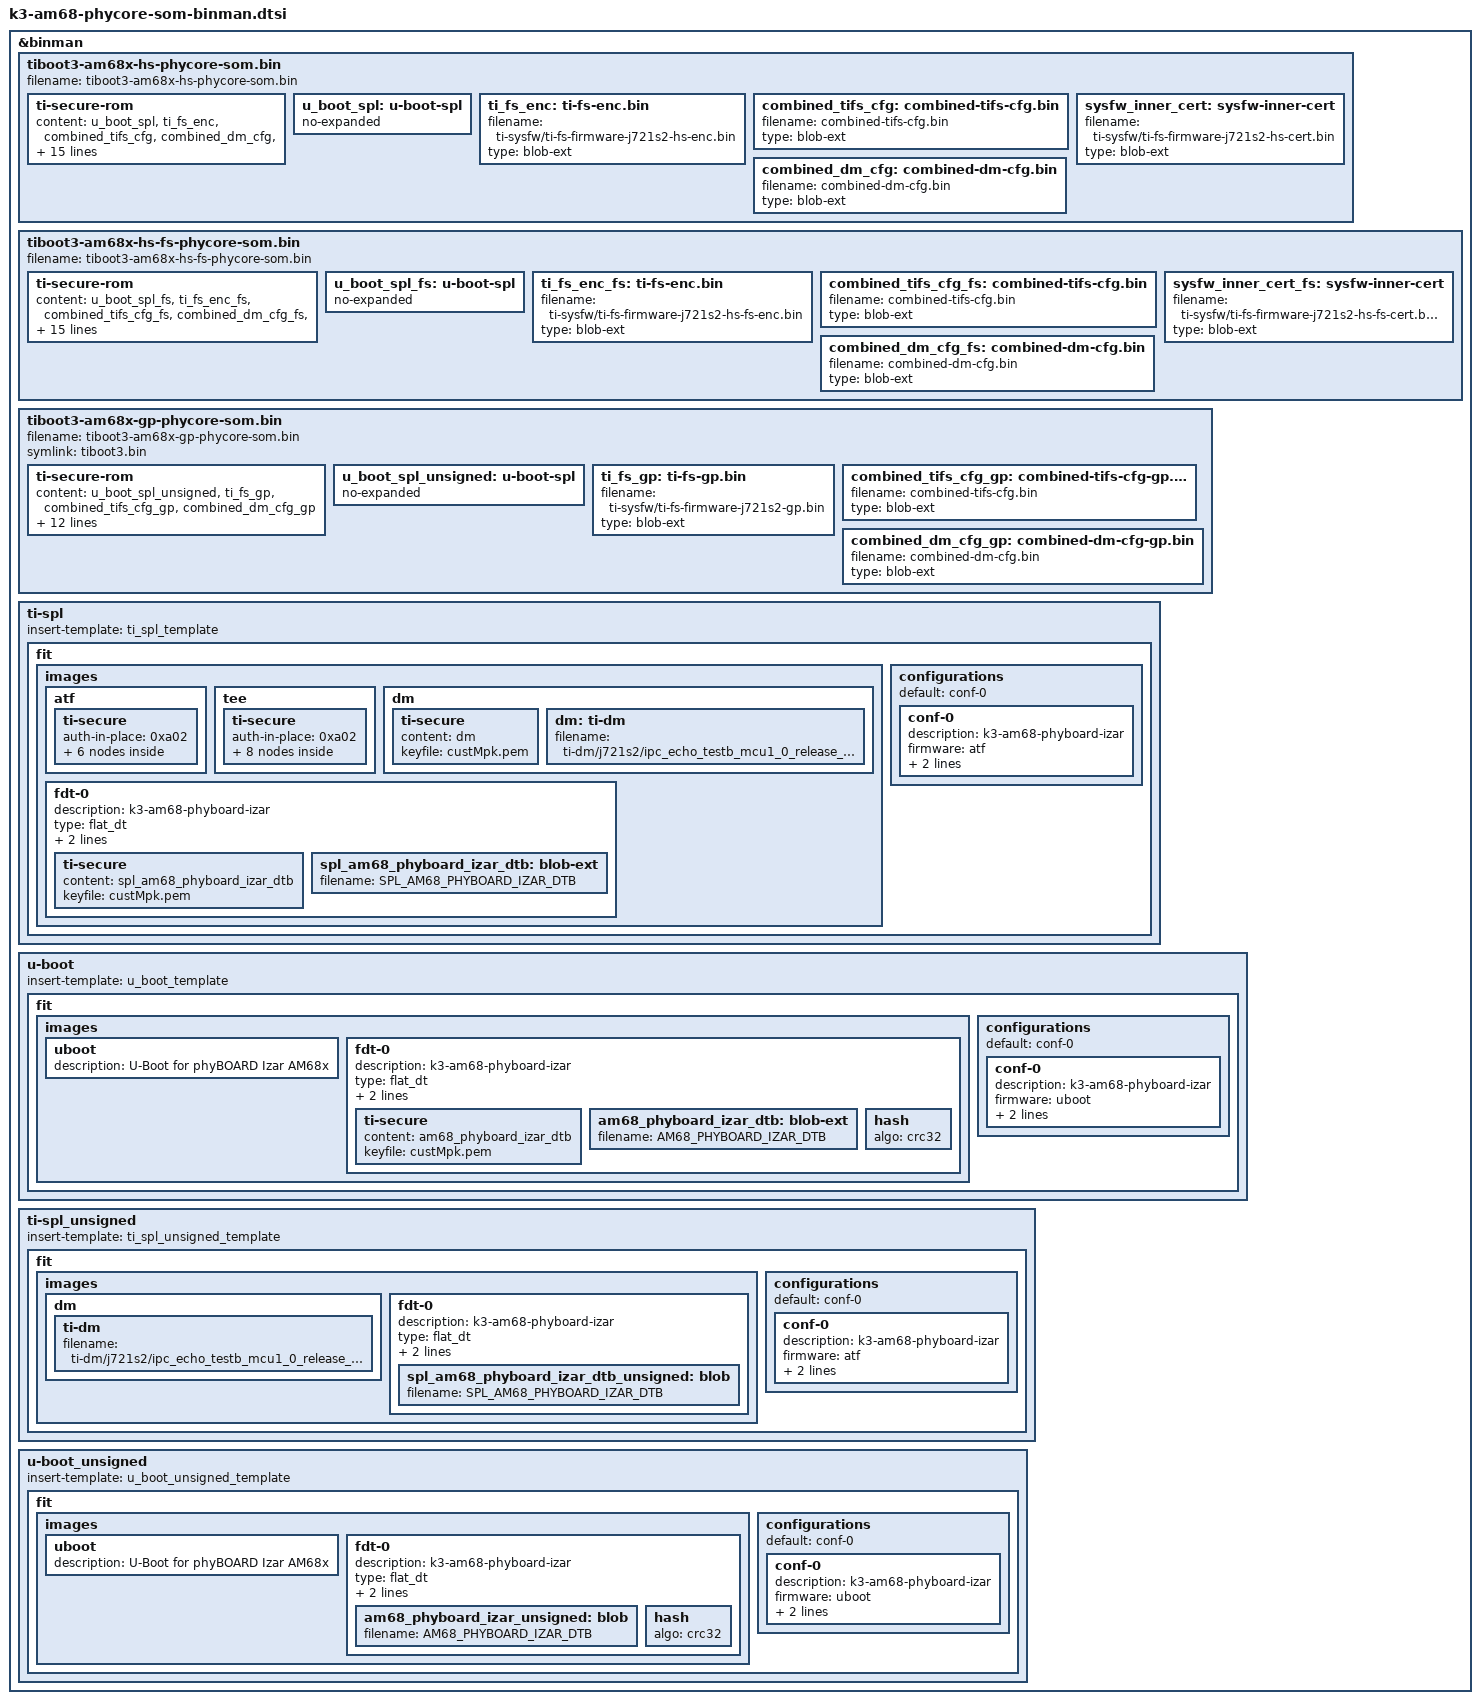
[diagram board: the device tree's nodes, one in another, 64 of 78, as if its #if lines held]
// SPDX-License-Identifier: GPL-2.0-only OR MIT
/*
 * Based on k3-j721s2-binman.dtsi
 *
 * Copyright (C) 2025 PHYTEC Messtechnik GmbH
 * Author: Dominik Haller <d.haller@phytec.de>
 */

#include "k3-binman.dtsi"

#ifdef CONFIG_TARGET_PHYCORE_AM68X_R5

&binman {
	tiboot3-am68x-hs-phycore-som.bin {
		filename = "tiboot3-am68x-hs-phycore-som.bin";
		ti-secure-rom {
			content = <&u_boot_spl>, <&ti_fs_enc>, <&combined_tifs_cfg>,
				<&combined_dm_cfg>, <&sysfw_inner_cert>;
			combined;
			dm-data;
			sysfw-inner-cert;
			keyfile = "custMpk.pem";
			sw-rev = <1>;
			content-sbl = <&u_boot_spl>;
			content-sysfw = <&ti_fs_enc>;
			content-sysfw-data = <&combined_tifs_cfg>;
			content-sysfw-inner-cert = <&sysfw_inner_cert>;
			content-dm-data = <&combined_dm_cfg>;
			load = <CONFIG_SPL_TEXT_BASE>;
			load-sysfw = <0x40000>;
			load-sysfw-data = <0x67000>;
			load-dm-data = <0x41c80000>;
		};
		u_boot_spl: u-boot-spl {
			no-expanded;
		};
		ti_fs_enc: ti-fs-enc.bin {
			filename = "ti-sysfw/ti-fs-firmware-j721s2-hs-enc.bin";
			type = "blob-ext";
		};
		combined_tifs_cfg: combined-tifs-cfg.bin {
			filename = "combined-tifs-cfg.bin";
			type = "blob-ext";
		};
		sysfw_inner_cert: sysfw-inner-cert {
			filename = "ti-sysfw/ti-fs-firmware-j721s2-hs-cert.bin";
			type = "blob-ext";
		};
		combined_dm_cfg: combined-dm-cfg.bin {
			filename = "combined-dm-cfg.bin";
			type = "blob-ext";
		};
	};
};

&binman {
	tiboot3-am68x-hs-fs-phycore-som.bin {
		filename = "tiboot3-am68x-hs-fs-phycore-som.bin";
		ti-secure-rom {
			content = <&u_boot_spl_fs>, <&ti_fs_enc_fs>, <&combined_tifs_cfg_fs>,
				<&combined_dm_cfg_fs>, <&sysfw_inner_cert_fs>;
			combined;
			dm-data;
			sysfw-inner-cert;
			keyfile = "custMpk.pem";
			sw-rev = <1>;
			content-sbl = <&u_boot_spl_fs>;
			content-sysfw = <&ti_fs_enc_fs>;
			content-sysfw-data = <&combined_tifs_cfg_fs>;
			content-sysfw-inner-cert = <&sysfw_inner_cert_fs>;
			content-dm-data = <&combined_dm_cfg_fs>;
			load = <CONFIG_SPL_TEXT_BASE>;
			load-sysfw = <0x40000>;
			load-sysfw-data = <0x67000>;
			load-dm-data = <0x41c80000>;
		};
		u_boot_spl_fs: u-boot-spl {
			no-expanded;
		};
		ti_fs_enc_fs: ti-fs-enc.bin {
			filename = "ti-sysfw/ti-fs-firmware-j721s2-hs-fs-enc.bin";
			type = "blob-ext";
		};
		combined_tifs_cfg_fs: combined-tifs-cfg.bin {
			filename = "combined-tifs-cfg.bin";
			type = "blob-ext";
		};
		sysfw_inner_cert_fs: sysfw-inner-cert {
			filename = "ti-sysfw/ti-fs-firmware-j721s2-hs-fs-cert.bin";
			type = "blob-ext";
		};
		combined_dm_cfg_fs: combined-dm-cfg.bin {
			filename = "combined-dm-cfg.bin";
			type = "blob-ext";
		};
	};
};

&binman {
	tiboot3-am68x-gp-phycore-som.bin {
		filename = "tiboot3-am68x-gp-phycore-som.bin";
		symlink = "tiboot3.bin";
		ti-secure-rom {
			content = <&u_boot_spl_unsigned>, <&ti_fs_gp>,
				<&combined_tifs_cfg_gp>, <&combined_dm_cfg_gp>;
			combined;
			dm-data;
			content-sbl = <&u_boot_spl_unsigned>;
			load = <CONFIG_SPL_TEXT_BASE>;
			content-sysfw = <&ti_fs_gp>;
			load-sysfw = <0x40000>;
			content-sysfw-data = <&combined_tifs_cfg_gp>;
			load-sysfw-data = <0x67000>;
			content-dm-data = <&combined_dm_cfg_gp>;
			load-dm-data = <0x41c80000>;
			sw-rev = <1>;
			keyfile = "ti-degenerate-key.pem";
		};
		u_boot_spl_unsigned: u-boot-spl {
			no-expanded;
		};
		ti_fs_gp: ti-fs-gp.bin {
			filename = "ti-sysfw/ti-fs-firmware-j721s2-gp.bin";
			type = "blob-ext";
		};
		combined_tifs_cfg_gp: combined-tifs-cfg-gp.bin {
			filename = "combined-tifs-cfg.bin";
			type = "blob-ext";
		};
		combined_dm_cfg_gp: combined-dm-cfg-gp.bin {
			filename = "combined-dm-cfg.bin";
			type = "blob-ext";
		};

	};
};

#endif

#ifdef CONFIG_TARGET_PHYCORE_AM68X_A72
#define SPL_AM68_PHYBOARD_IZAR_DTB "spl/dts/ti/k3-am68-phyboard-izar.dtb"
#define AM68_PHYBOARD_IZAR_DTB "u-boot.dtb"

&binman {
	ti-spl {
		insert-template = <&ti_spl_template>;

		fit {
			images {
				atf {
					ti-secure {
						auth-in-place = <0xa02>;

						firewall-257-0 {
							/* cpu_0_cpu_0_msmc Background Firewall */
							insert-template = <&firewall_bg_1>;
							id = <257>;
							region = <0>;
						};

						firewall-257-1 {
							/* cpu_0_cpu_0_msmc Foreground Firewall */
							insert-template = <&firewall_armv8_atf_fg>;
							id = <257>;
							region = <1>;
						};

						firewall-284-0 {
							/* dru_0_msmc Background Firewall */
							insert-template = <&firewall_bg_3>;
							id = <284>;
							region = <0>;
						};

						firewall-284-1 {
							/* dru_0_msmc Foreground Firewall */
							insert-template = <&firewall_armv8_atf_fg>;
							id = <284>;
							region = <1>;
						};

						/*	firewall-5140-0 {
						 *		nb_slv0__mem0 Background Firewall
						 *		Already configured by the secure entity
						 *	};
						 */

						firewall-5140-1 {
							/* nb_slv0__mem0 Foreground Firewall */
							insert-template = <&firewall_armv8_atf_fg>;
							id = <5140>;
							region = <1>;
						};

						/*	firewall-5140-0 {
						 *		nb_slv1__mem0 Background Firewall
						 *		Already configured by the secure entity
						 *	};
						 */

						firewall-5141-1 {
							/* nb_slv1__mem0 Foreground Firewall */
							insert-template = <&firewall_armv8_atf_fg>;
							id = <5141>;
							region = <1>;
						};

					};
				};

				tee {
					ti-secure {
						auth-in-place = <0xa02>;

						firewall-257-2 {
							/* cpu_0_cpu_0_msmc Foreground Firewall */
							insert-template = <&firewall_armv8_optee_fg>;
							id = <257>;
							region = <2>;
						};

						firewall-284-2 {
							/* dru_0_msmc Foreground Firewall */
							insert-template = <&firewall_armv8_optee_fg>;
							id = <284>;
							region = <2>;
						};

						firewall-5142-0 {
							/* nb_slv2__mem0 Background Firewall - 0 */
							insert-template = <&firewall_bg_3>;
							id = <5142>;
							region = <0>;
						};

						firewall-5142-1 {
							/* nb_slv2__mem0 Foreground Firewall */
							insert-template = <&firewall_armv8_optee_fg>;
							id = <5142>;
							region = <1>;
						};

						firewall-5143-0 {
							/* nb_slv3__mem0 Background Firewall - 0 */
							insert-template = <&firewall_bg_3>;
							id = <5143>;
							region = <0>;
						};

						firewall-5143-1 {
							/* nb_slv3__mem0 Foreground Firewall */
							insert-template = <&firewall_armv8_optee_fg>;
							id = <5143>;
							region = <1>;
						};

						firewall-5144-0 {
							/* nb_slv4__mem0 Background Firewall - 0 */
							insert-template = <&firewall_bg_3>;
							id = <5144>;
							region = <0>;
						};

						firewall-5144-1 {
							/* nb_slv4__mem0 Foreground Firewall */
							insert-template = <&firewall_armv8_optee_fg>;
							id = <5144>;
							region = <1>;
						};

					};
				};
				dm {
					ti-secure {
						content = <&dm>;
						keyfile = "custMpk.pem";
					};
					dm: ti-dm {
						filename = "ti-dm/j721s2/ipc_echo_testb_mcu1_0_release_strip.xer5f";
					};
				};

				fdt-0 {
					description = "k3-am68-phyboard-izar";
					type = "flat_dt";
					arch = "arm";
					compression = "none";
					ti-secure {
						content = <&spl_am68_phyboard_izar_dtb>;
						keyfile = "custMpk.pem";
					};
					spl_am68_phyboard_izar_dtb: blob-ext {
						filename = SPL_AM68_PHYBOARD_IZAR_DTB;
					};

				};
			};

			configurations {
				default = "conf-0";

				conf-0 {
					description = "k3-am68-phyboard-izar";
					firmware = "atf";
					loadables = "tee", "dm", "spl";
					fdt = "fdt-0";
				};
			};
		};
	};
};

&binman {
	u-boot {
		insert-template = <&u_boot_template>;

		fit {
			images {
				uboot {
					description = "U-Boot for phyBOARD Izar AM68x";
				};

				fdt-0 {
					description = "k3-am68-phyboard-izar";
					type = "flat_dt";
					arch = "arm";
					compression = "none";
					ti-secure {
						content = <&am68_phyboard_izar_dtb>;
						keyfile = "custMpk.pem";
					};
					am68_phyboard_izar_dtb: blob-ext {
						filename = AM68_PHYBOARD_IZAR_DTB;
					};

					hash {
						algo = "crc32";
					};
				};
			};

			configurations {
				default = "conf-0";

				conf-0 {
					description = "k3-am68-phyboard-izar";
					firmware = "uboot";
					loadables = "uboot";
					fdt = "fdt-0";
				};
			};
		};
	};
};

&binman {
	ti-spl_unsigned {
		insert-template = <&ti_spl_unsigned_template>;

		fit {
			images {
				dm {
					ti-dm {
						filename = "ti-dm/j721s2/ipc_echo_testb_mcu1_0_release_strip.xer5f";
					};
				};

				fdt-0 {
					description = "k3-am68-phyboard-izar";
					type = "flat_dt";
					arch = "arm";
					compression = "none";
					spl_am68_phyboard_izar_dtb_unsigned: blob {
						filename = SPL_AM68_PHYBOARD_IZAR_DTB;
					};
				};
			};

			configurations {
				default = "conf-0";

				conf-0 {
					description = "k3-am68-phyboard-izar";
					firmware = "atf";
					loadables = "tee", "dm", "spl";
					fdt = "fdt-0";
				};
			};
		};
	};
};

&binman {
	u-boot_unsigned {
		insert-template = <&u_boot_unsigned_template>;

		fit {
			images {
				uboot {
					description = "U-Boot for phyBOARD Izar AM68x";
				};

				fdt-0 {
					description = "k3-am68-phyboard-izar";
					type = "flat_dt";
					arch = "arm";
					compression = "none";
					am68_phyboard_izar_unsigned: blob {
						filename = AM68_PHYBOARD_IZAR_DTB;
					};
					hash {
						algo = "crc32";
					};
				};
			};

			configurations {
				default = "conf-0";

				conf-0 {
					description = "k3-am68-phyboard-izar";
					firmware = "uboot";
					loadables = "uboot";
					fdt = "fdt-0";
				};
			};
		};
	};
};
#endif
